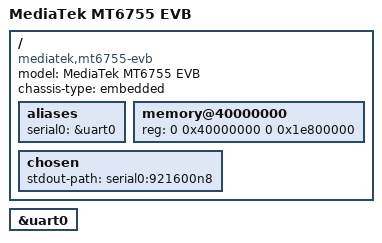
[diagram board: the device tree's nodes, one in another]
// SPDX-License-Identifier: GPL-2.0-only
/*
 * Copyright (c) 2016 MediaTek Inc.
 * Author: Mars.C <mars.cheng@mediatek.com>
 */

/dts-v1/;
#include "mt6755.dtsi"

/ {
	model = "MediaTek MT6755 EVB";
	chassis-type = "embedded";
	compatible = "mediatek,mt6755-evb", "mediatek,mt6755";

	aliases {
		serial0 = &uart0;
	};

	memory@40000000 {
		device_type = "memory";
		reg = <0 0x40000000 0 0x1e800000>;
	};

	chosen {
		stdout-path = "serial0:921600n8";
	};
};

&uart0 {
	status = "okay";
};
